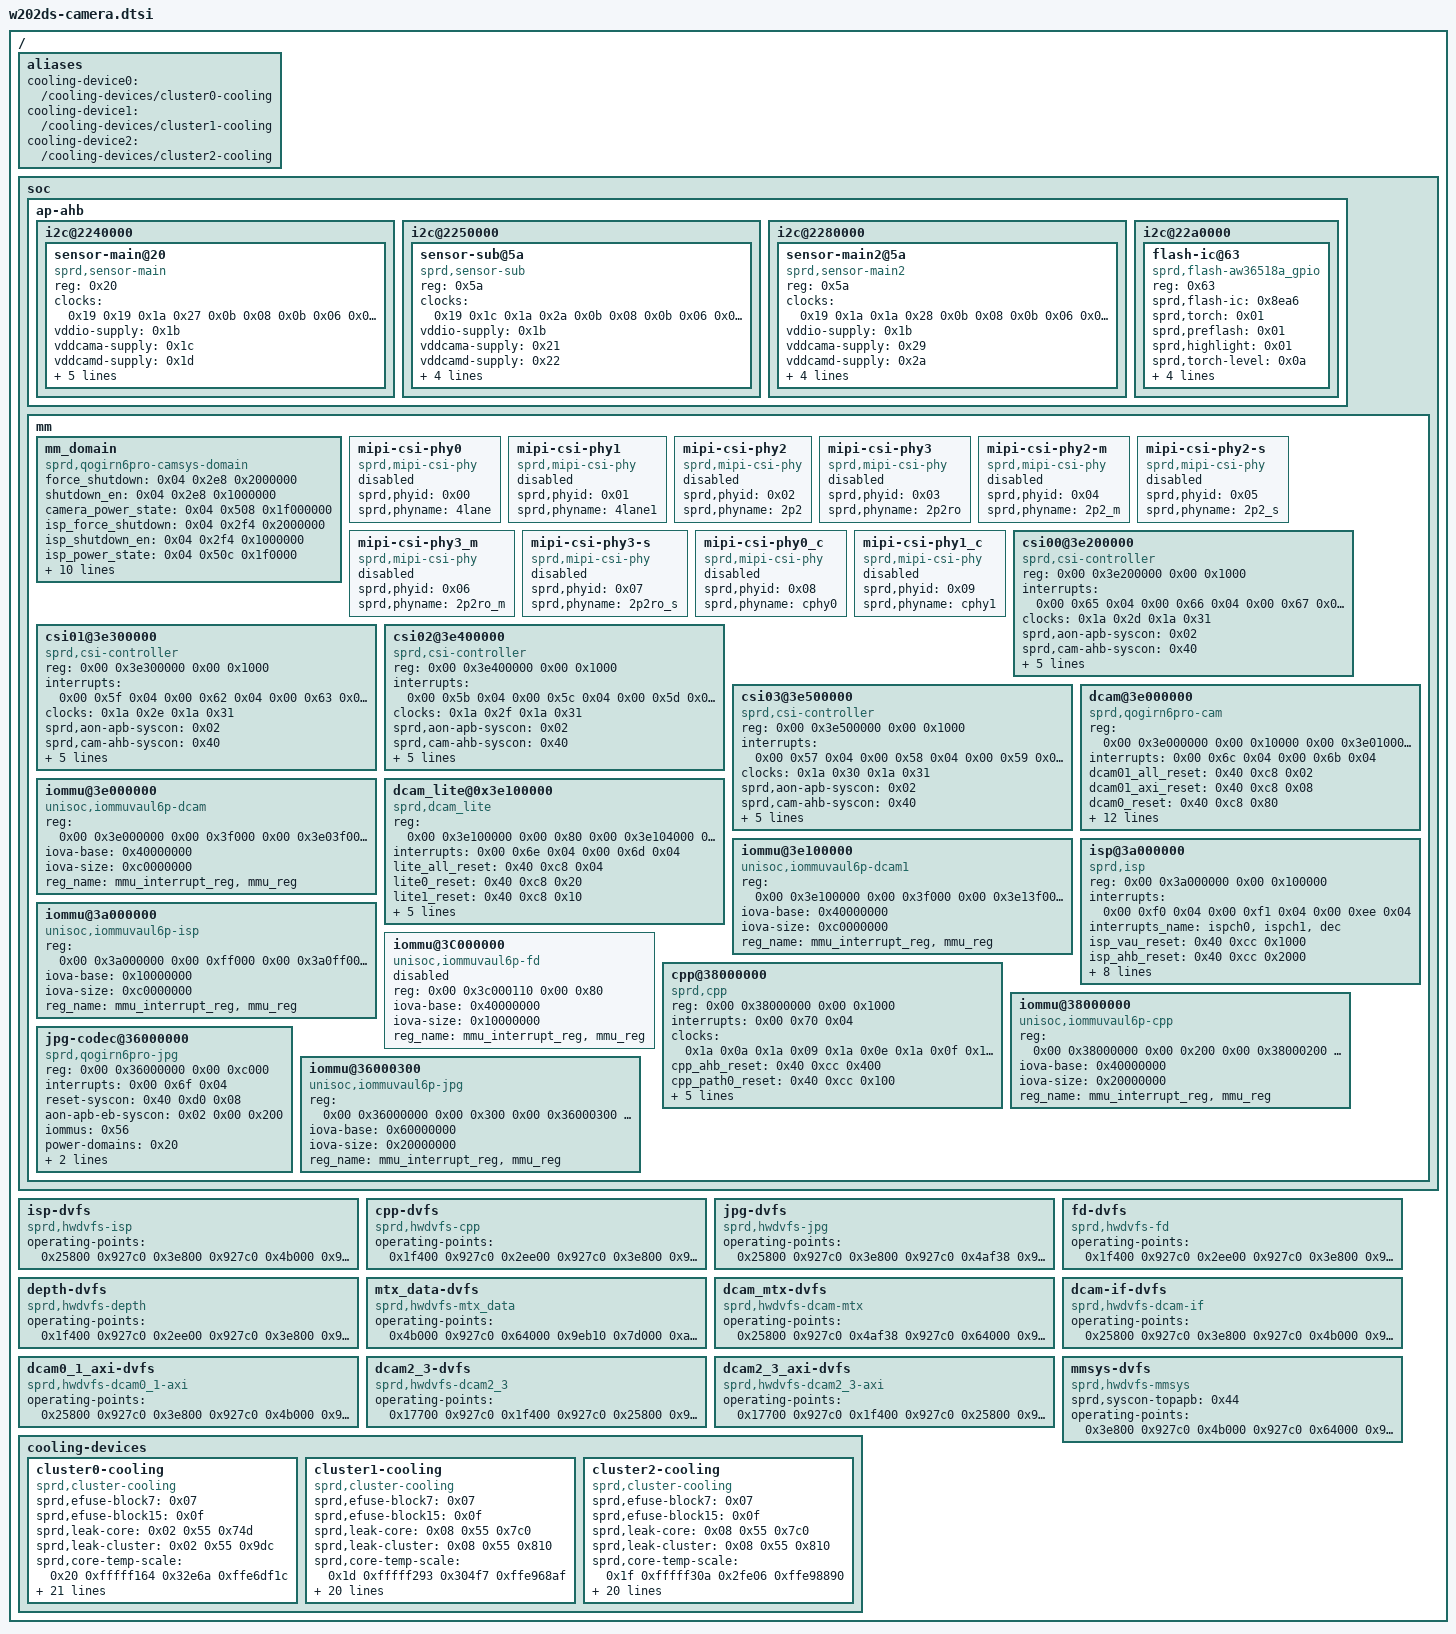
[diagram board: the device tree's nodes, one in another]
// W202DS imported hardware layout; driver status is documented in ../README.md.
/ {
	aliases {
		cooling-device0 = "/cooling-devices/cluster0-cooling";
		cooling-device1 = "/cooling-devices/cluster1-cooling";
		cooling-device2 = "/cooling-devices/cluster2-cooling";
	};
	soc {
		ap-ahb {
			i2c@2240000 {
				sensor-main@20 {
					compatible = "sprd,sensor-main";
					reg = <0x20>;
					clock-names = "clk_src", "sensor_eb", "clk_96m", "clk_64m", "clk_51m2", "clk_48m", "clk_26m";
					clocks = <0x19 0x19 0x1a 0x27 0x0b 0x08 0x0b 0x06 0x0b 0x05 0x0b 0x04 0x09>;
					vddio-supply = <0x1b>;
					vddcama-supply = <0x1c>;
					vddcamd-supply = <0x1d>;
					vddcammot-supply = <0x1e>;
					reset-gpios = <0x0c 0x28 0x00>;
					sprd,phyid = <0x02>;
					csi = <0x1f>;
					power-domains = <0x20>;
					phandle = <0x148>;
				};
			};
			i2c@2250000 {
				sensor-sub@5a {
					compatible = "sprd,sensor-sub";
					reg = <0x5a>;
					clock-names = "clk_src", "sensor_eb", "clk_96m", "clk_64m", "clk_51m2", "clk_48m", "clk_26m";
					clocks = <0x19 0x1c 0x1a 0x2a 0x0b 0x08 0x0b 0x06 0x0b 0x05 0x0b 0x04 0x09>;
					vddio-supply = <0x1b>;
					vddcama-supply = <0x21>;
					vddcamd-supply = <0x22>;
					reset-gpios = <0x0c 0x27 0x00>;
					sprd,phyid = <0x03>;
					csi = <0x23>;
					power-domains = <0x20>;
					phandle = <0x14a>;
				};
			};
			i2c@2280000 {
				sensor-main2@5a {
					compatible = "sprd,sensor-main2";
					reg = <0x5a>;
					clock-names = "clk_src", "sensor_eb", "clk_96m", "clk_64m", "clk_51m2", "clk_48m", "clk_26m";
					clocks = <0x19 0x1a 0x1a 0x28 0x0b 0x08 0x0b 0x06 0x0b 0x05 0x0b 0x04 0x09>;
					vddio-supply = <0x1b>;
					vddcama-supply = <0x29>;
					vddcamd-supply = <0x2a>;
					reset-gpios = <0x0c 0x29 0x00>;
					sprd,phyid = <0x01>;
					csi = <0x2b>;
					power-domains = <0x20>;
					phandle = <0x14f>;
				};
			};
			i2c@22a0000 {
				flash-ic@63 {
					compatible = "sprd,flash-aw36518a_gpio";
					reg = <0x63>;
					sprd,flash-ic = <0x8ea6>;
					sprd,torch = <0x01>;
					sprd,preflash = <0x01>;
					sprd,highlight = <0x01>;
					sprd,torch-level = <0x0a>;
					sprd,preflash-level = <0x0a>;
					sprd,highlight-level = <0x0f>;
					sprd,lvfm-enable = <0x01>;
					flash-torch-en-gpios = <0x0c 0x6f 0x00>;
					phandle = <0x153>;
				};
			};
		};
		mm {
			mm_domain {
				compatible = "sprd,qogirn6pro-camsys-domain";
				force_shutdown = <0x04 0x2e8 0x2000000>;
				shutdown_en = <0x04 0x2e8 0x1000000>;
				camera_power_state = <0x04 0x508 0x1f000000>;
				isp_force_shutdown = <0x04 0x2f4 0x2000000>;
				isp_shutdown_en = <0x04 0x2f4 0x1000000>;
				isp_power_state = <0x04 0x50c 0x1f0000>;
				dcam_force_shutdown = <0x04 0x2ec 0x2000000>;
				dcam_shutdown_en = <0x04 0x2ec 0x1000000>;
				dcam_power_state = <0x04 0x50c 0x1f>;
				aon_apb_mm_eb = <0x02 0x00 0x200>;
				mm_ahb_dvfs_en = <0x40 0x00 0x08>;
				cam_sw_dvfs_ack = <0x41 0x38 0x100>;
				cam_sw_dvfs_volt = <0x41 0x38 0xf0>;
				cam_sw_dvfs_req = <0x41 0x38 0x01>;
				clock-names = "clk_mm_eb", "clk_ckg_en", "clk_mm_mtx_data_en", "clk_mm_mtx_data", "clk_blk_cfg_en", "sys_cfg_mtx_busmon_en", "sys_mst_busmon_en", "clk_mm_mtx_defalut", "clk_mm_mtx_parent", "clk_mm_sys_cfg", "clk_mm_sys_cfg_parent";
				clocks = <0x11 0x07 0x1a 0x01 0x1a 0x08 0x19 0x16 0x1a 0x0f 0x1a 0x05 0x1a 0x06 0x0b 0x0a 0x0b 0x0f 0x19 0x18 0x0b 0x09>;
				#power-domain-cells = <0x00>;
				status = "okay";
				phandle = <0x20>;
			};
			mipi-csi-phy0 {
				compatible = "sprd,mipi-csi-phy";
				sprd,phyid = <0x00>;
				sprd,phyname = "4lane";
				status = "disabled";
				phandle = <0x15b>;
			};
			mipi-csi-phy1 {
				compatible = "sprd,mipi-csi-phy";
				sprd,phyid = <0x01>;
				sprd,phyname = "4lane1";
				status = "disabled";
				phandle = <0x15c>;
			};
			mipi-csi-phy2 {
				compatible = "sprd,mipi-csi-phy";
				sprd,phyid = <0x02>;
				sprd,phyname = "2p2";
				status = "disabled";
				phandle = <0x15d>;
			};
			mipi-csi-phy3 {
				compatible = "sprd,mipi-csi-phy";
				sprd,phyid = <0x03>;
				sprd,phyname = "2p2ro";
				status = "disabled";
				phandle = <0x15e>;
			};
			mipi-csi-phy2-m {
				compatible = "sprd,mipi-csi-phy";
				sprd,phyid = <0x04>;
				sprd,phyname = "2p2_m";
				status = "disabled";
				phandle = <0x15f>;
			};
			mipi-csi-phy2-s {
				compatible = "sprd,mipi-csi-phy";
				sprd,phyid = <0x05>;
				sprd,phyname = "2p2_s";
				status = "disabled";
				phandle = <0x160>;
			};
			mipi-csi-phy3_m {
				compatible = "sprd,mipi-csi-phy";
				sprd,phyid = <0x06>;
				sprd,phyname = "2p2ro_m";
				status = "disabled";
				phandle = <0x161>;
			};
			mipi-csi-phy3-s {
				compatible = "sprd,mipi-csi-phy";
				sprd,phyid = <0x07>;
				sprd,phyname = "2p2ro_s";
				status = "disabled";
				phandle = <0x162>;
			};
			mipi-csi-phy0_c {
				compatible = "sprd,mipi-csi-phy";
				sprd,phyid = <0x08>;
				sprd,phyname = "cphy0";
				status = "disabled";
				phandle = <0x163>;
			};
			mipi-csi-phy1_c {
				compatible = "sprd,mipi-csi-phy";
				sprd,phyid = <0x09>;
				sprd,phyname = "cphy1";
				status = "disabled";
				phandle = <0x164>;
			};
			csi00@3e200000 {
				compatible = "sprd,csi-controller";
				reg = <0x00 0x3e200000 0x00 0x1000>;
				interrupts = <0x00 0x65 0x04 0x00 0x66 0x04 0x00 0x67 0x04 0x00 0x68 0x04>;
				clock-names = "clk_csi_eb", "mipi_csi_src_eb";
				clocks = <0x1a 0x2d 0x1a 0x31>;
				sprd,aon-apb-syscon = <0x02>;
				sprd,cam-ahb-syscon = <0x40>;
				sprd,anlg_phy_g4l_controller = <0x47>;
				sprd,anlg_phy_g4_controller = <0x48>;
				sprd,csi-id = <0x00>;
				sprd,dcam-id = <0x00>;
				sprd,ip-version = <0x301>;
				status = "okay";
				phandle = <0x166>;
			};
			csi01@3e300000 {
				compatible = "sprd,csi-controller";
				reg = <0x00 0x3e300000 0x00 0x1000>;
				interrupts = <0x00 0x5f 0x04 0x00 0x62 0x04 0x00 0x63 0x04 0x00 0x64 0x04>;
				clock-names = "clk_csi_eb", "mipi_csi_src_eb";
				clocks = <0x1a 0x2e 0x1a 0x31>;
				sprd,aon-apb-syscon = <0x02>;
				sprd,cam-ahb-syscon = <0x40>;
				sprd,anlg_phy_g4_controller = <0x48>;
				sprd,anlg_phy_g4l_controller = <0x47>;
				sprd,csi-id = <0x01>;
				sprd,dcam-id = <0x01>;
				sprd,ip-version = <0x301>;
				status = "okay";
				phandle = <0x2b>;
			};
			csi02@3e400000 {
				compatible = "sprd,csi-controller";
				reg = <0x00 0x3e400000 0x00 0x1000>;
				interrupts = <0x00 0x5b 0x04 0x00 0x5c 0x04 0x00 0x5d 0x04 0x00 0x5e 0x04>;
				clock-names = "clk_csi_eb", "mipi_csi_src_eb";
				clocks = <0x1a 0x2f 0x1a 0x31>;
				sprd,aon-apb-syscon = <0x02>;
				sprd,cam-ahb-syscon = <0x40>;
				sprd,anlg_phy_g4l_controller = <0x47>;
				sprd,anlg_phy_g4_controller = <0x48>;
				sprd,csi-id = <0x02>;
				sprd,dcam-id = <0x02>;
				sprd,ip-version = <0x301>;
				status = "okay";
				phandle = <0x1f>;
			};
			csi03@3e500000 {
				compatible = "sprd,csi-controller";
				reg = <0x00 0x3e500000 0x00 0x1000>;
				interrupts = <0x00 0x57 0x04 0x00 0x58 0x04 0x00 0x59 0x04 0x00 0x5a 0x04>;
				clock-names = "clk_csi_eb", "mipi_csi_src_eb";
				clocks = <0x1a 0x30 0x1a 0x31>;
				sprd,aon-apb-syscon = <0x02>;
				sprd,cam-ahb-syscon = <0x40>;
				sprd,anlg_phy_g4_controller = <0x48>;
				sprd,anlg_phy_g4l_controller = <0x47>;
				sprd,csi-id = <0x03>;
				sprd,dcam-id = <0x03>;
				sprd,ip-version = <0x301>;
				status = "okay";
				phandle = <0x23>;
			};
			dcam@3e000000 {
				compatible = "sprd,qogirn6pro-cam";
				reg = <0x00 0x3e000000 0x00 0x10000 0x00 0x3e010000 0x00 0x10000 0x00 0x3e030000 0x00 0xb0 0x00 0x3e038000 0x00 0x40>;
				reg-names = "dcam0_reg", "dcam1_reg", "dcam01_axi_ctrl_reg", "fmcu_ctrl_reg";
				interrupts = <0x00 0x6c 0x04 0x00 0x6b 0x04>;
				interrupt-names = "dcam0", "dcam1";
				dcam01_all_reset = <0x40 0xc8 0x02>;
				dcam01_axi_reset = <0x40 0xc8 0x08>;
				dcam0_reset = <0x40 0xc8 0x80>;
				dcam1_reset = <0x40 0xc8 0x40>;
				clock-names = "dcam_eb", "dcam_blk_cfg_en", "dcam_tck_en", "dcam_mtx_en", "dcam_clk", "dcam_clk_parent", "dcam_axi_clk", "dcam_axi_clk_parent", "dcam_mtx_clk", "dcam_mtx_clk_parent", "dcam_blk_cfg_clk", "dcam_blk_cfg_clk_parent";
				clocks = <0x1a 0x21 0x1a 0x26 0x1a 0x2c 0x1a 0x24 0x19 0x0a 0x0b 0x0f 0x19 0x0b 0x0b 0x0f 0x19 0x14 0x0b 0x0f 0x19 0x15 0x0b 0x09>;
				sprd,cam-ahb-syscon = <0x40>;
				sprd,csi-switch = <0x49>;
				sprd,isp = <0x4a>;
				sprd,dcam-lite = <0x4b>;
				sprd,dcam-count = <0x02>;
				sprd,dcam-superzoom = <0x02>;
				sprd,project-id = <0x04>;
				iommus = <0x4c>;
				power-domains = <0x20>;
				status = "okay";
				phandle = <0x167>;
			};
			iommu@3e000000 {
				compatible = "unisoc,iommuvaul6p-dcam";
				reg = <0x00 0x3e000000 0x00 0x3f000 0x00 0x3e03f000 0x00 0xb0>;
				iova-base = <0x40000000>;
				iova-size = <0xc0000000>;
				reg_name = "mmu_interrupt_reg", "mmu_reg";
				status = "okay";
				#iommu-cells = <0x00>;
				phandle = <0x4c>;
			};
			dcam_lite@0x3e100000 {
				compatible = "sprd,dcam_lite";
				reg = <0x00 0x3e100000 0x00 0x80 0x00 0x3e104000 0x00 0x80 0x00 0x3e108000 0x00 0x50>;
				reg-names = "dcam2_reg", "dcam3_reg", "dcam23_axi_ctrl_reg";
				interrupts = <0x00 0x6e 0x04 0x00 0x6d 0x04>;
				interrupt-names = "dcam2", "dcam3";
				lite_all_reset = <0x40 0xc8 0x04>;
				lite0_reset = <0x40 0xc8 0x20>;
				lite1_reset = <0x40 0xc8 0x10>;
				clock-names = "dcam_lite_eb", "dcam_lite_mtx_en", "dcam_lite_clk", "dcam_lite_clk_parent", "dcam_lite_axi_clk", "dcam_lite_axi_clk_parent";
				clocks = <0x1a 0x22 0x1a 0x25 0x19 0x0c 0x0b 0x0c 0x19 0x0d 0x0b 0x0c>;
				sprd,dcam-lite-count = <0x02>;
				iommus = <0x4d>;
				power-domains = <0x20>;
				status = "okay";
				phandle = <0x4b>;
			};
			iommu@3e100000 {
				compatible = "unisoc,iommuvaul6p-dcam1";
				reg = <0x00 0x3e100000 0x00 0x3f000 0x00 0x3e13f000 0x00 0xb0>;
				iova-base = <0x40000000>;
				iova-size = <0xc0000000>;
				reg_name = "mmu_interrupt_reg", "mmu_reg";
				status = "okay";
				#iommu-cells = <0x00>;
				phandle = <0x4d>;
			};
			isp@3a000000 {
				compatible = "sprd,isp";
				reg = <0x00 0x3a000000 0x00 0x100000>;
				interrupts = <0x00 0xf0 0x04 0x00 0xf1 0x04 0x00 0xee 0x04>;
				interrupts_name = "ispch0", "ispch1", "dec";
				isp_vau_reset = <0x40 0xcc 0x1000>;
				isp_ahb_reset = <0x40 0xcc 0x2000>;
				reset = <0x40 0xcc 0x4000>;
				sys_h2p_db_soft_rst = <0x40 0xd0 0x04>;
				clock-names = "isp_eb", "isp_mtx_en", "isp_tck_en", "isp_clk", "isp_clk_153m6", "isp_clk_256m", "isp_clk_307m2", "isp_clk_409m6", "isp_clk_512m", "isp_clk_parent";
				clocks = <0x1a 0x09 0x1a 0x0e 0x1a 0x13 0x19 0x06 0x0b 0x0a 0x0b 0x0c 0x0b 0x0d 0x0b 0x15 0x0b 0x0f 0x0b 0x0f>;
				sprd,cam-ahb-syscon = <0x40>;
				sprd,isp-count = <0x01>;
				iommus = <0x4e>;
				power-domains = <0x20>;
				status = "okay";
				phandle = <0x4a>;
			};
			iommu@3a000000 {
				compatible = "unisoc,iommuvaul6p-isp";
				reg = <0x00 0x3a000000 0x00 0xff000 0x00 0x3a0ff000 0x00 0xb0>;
				iova-base = <0x10000000>;
				iova-size = <0xc0000000>;
				reg_name = "mmu_interrupt_reg", "mmu_reg";
				status = "okay";
				#iommu-cells = <0x00>;
				phandle = <0x4e>;
			};
			iommu@3C000000 {
				compatible = "unisoc,iommuvaul6p-fd";
				reg = <0x00 0x3c000110 0x00 0x80>;
				iova-base = <0x40000000>;
				iova-size = <0x10000000>;
				reg_name = "mmu_interrupt_reg", "mmu_reg";
				status = "disabled";
				#iommu-cells = <0x00>;
				phandle = <0x168>;
			};
			cpp@38000000 {
				compatible = "sprd,cpp";
				reg = <0x00 0x38000000 0x00 0x1000>;
				interrupts = <0x00 0x70 0x04>;
				clock-names = "cpp_eb", "cpp_axi_eb", "isp_mtx_en", "isp_blk_cfg_en", "cpp_clk", "cpp_clk_parent";
				clocks = <0x1a 0x0a 0x1a 0x09 0x1a 0x0e 0x1a 0x0f 0x19 0x07 0x0b 0x0e>;
				cpp_ahb_reset = <0x40 0xcc 0x400>;
				cpp_path0_reset = <0x40 0xcc 0x100>;
				cpp_path1_reset = <0x40 0xcc 0x80>;
				cpp_dma_soft_set = <0x40 0xcc 0x40>;
				sprd,cam-ahb-syscon = <0x40>;
				iommus = <0x4f>;
				power-domains = <0x20>;
				status = "okay";
				phandle = <0x169>;
			};
			iommu@38000000 {
				compatible = "unisoc,iommuvaul6p-cpp";
				reg = <0x00 0x38000000 0x00 0x200 0x00 0x38000200 0x00 0x80>;
				iova-base = <0x40000000>;
				iova-size = <0x20000000>;
				reg_name = "mmu_interrupt_reg", "mmu_reg";
				status = "okay";
				#iommu-cells = <0x00>;
				phandle = <0x4f>;
			};
			jpg-codec@36000000 {
				compatible = "sprd,qogirn6pro-jpg";
				reg = <0x00 0x36000000 0x00 0xc000>;
				interrupts = <0x00 0x6f 0x04>;
				reset-syscon = <0x40 0xd0 0x08>;
				aon-apb-eb-syscon = <0x02 0x00 0x200>;
				iommus = <0x56>;
				power-domains = <0x20>;
				status = "okay";
				clock-names = "jpg_domain_eb", "jpg_dev_eb", "jpg_ckg_eb", "jpg_clk", "clk_src_153m6", "clk_src_256m", "clk_src_307m2", "clk_src_409m6", "clk_src_512m";
				clocks = <0x11 0x07 0x1a 0x00 0x1a 0x01 0x19 0x17 0x0b 0x0a 0x0b 0x0c 0x0b 0x0d 0x0b 0x15 0x0b 0x0f>;
				phandle = <0x16d>;
			};
			iommu@36000300 {
				compatible = "unisoc,iommuvaul6p-jpg";
				reg = <0x00 0x36000000 0x00 0x300 0x00 0x36000300 0x00 0x80>;
				iova-base = <0x60000000>;
				iova-size = <0x20000000>;
				reg_name = "mmu_interrupt_reg", "mmu_reg";
				status = "okay";
				#iommu-cells = <0x00>;
				phandle = <0x56>;
			};
		};
	};
	isp-dvfs {
		compatible = "sprd,hwdvfs-isp";
		operating-points = <0x25800 0x927c0 0x3e800 0x927c0 0x4b000 0x927c0 0x64000 0x9eb10 0x7d000 0xb71b0>;
		phandle = <0x217>;
	};
	cpp-dvfs {
		compatible = "sprd,hwdvfs-cpp";
		operating-points = <0x1f400 0x927c0 0x2ee00 0x927c0 0x3e800 0x927c0 0x4b000 0x9eb10 0x5dc00 0xaae60>;
		phandle = <0x218>;
	};
	jpg-dvfs {
		compatible = "sprd,hwdvfs-jpg";
		operating-points = <0x25800 0x927c0 0x3e800 0x927c0 0x4af38 0x927c0 0x64000 0x9eb10 0x7d000 0xaae60>;
		phandle = <0x219>;
	};
	fd-dvfs {
		compatible = "sprd,hwdvfs-fd";
		operating-points = <0x1f400 0x927c0 0x2ee00 0x927c0 0x3e800 0x927c0 0x4b000 0x9eb10 0x5dc00 0xaae60>;
		phandle = <0x21a>;
	};
	depth-dvfs {
		compatible = "sprd,hwdvfs-depth";
		operating-points = <0x1f400 0x927c0 0x2ee00 0x927c0 0x3e800 0x927c0 0x4b000 0x9eb10 0x5dc00 0xaae60>;
		phandle = <0x21b>;
	};
	mtx_data-dvfs {
		compatible = "sprd,hwdvfs-mtx_data";
		operating-points = <0x4b000 0x927c0 0x64000 0x9eb10 0x7d000 0xaae60>;
		phandle = <0x21c>;
	};
	dcam_mtx-dvfs {
		compatible = "sprd,hwdvfs-dcam-mtx";
		operating-points = <0x25800 0x927c0 0x4af38 0x927c0 0x64000 0x9eb10 0x7d000 0xaae60>;
		phandle = <0x21d>;
	};
	dcam-if-dvfs {
		compatible = "sprd,hwdvfs-dcam-if";
		operating-points = <0x25800 0x927c0 0x3e800 0x927c0 0x4b000 0x927c0 0x64000 0x9eb10 0x7d000 0xaae60>;
		phandle = <0x21e>;
	};
	dcam0_1_axi-dvfs {
		compatible = "sprd,hwdvfs-dcam0_1-axi";
		operating-points = <0x25800 0x927c0 0x3e800 0x927c0 0x4b000 0x927c0 0x64000 0x9eb10 0x7d000 0xaae60>;
		phandle = <0x21f>;
	};
	dcam2_3-dvfs {
		compatible = "sprd,hwdvfs-dcam2_3";
		operating-points = <0x17700 0x927c0 0x1f400 0x927c0 0x25800 0x927c0 0x2ee00 0x9eb10 0x3e800 0xaae60>;
		phandle = <0x220>;
	};
	dcam2_3_axi-dvfs {
		compatible = "sprd,hwdvfs-dcam2_3-axi";
		operating-points = <0x17700 0x927c0 0x1f400 0x927c0 0x25800 0x927c0 0x2ee00 0x9eb10 0x3e800 0xaae60>;
		phandle = <0x221>;
	};
	mmsys-dvfs {
		compatible = "sprd,hwdvfs-mmsys";
		sprd,syscon-topapb = <0x44>;
		operating-points = <0x3e800 0x927c0 0x4b000 0x927c0 0x64000 0x9eb10 0x7d000 0xb71b0>;
		phandle = <0x225>;
	};
	cooling-devices {
		cluster0-cooling {
			compatible = "sprd,cluster-cooling";
			#cooling-cells = <0x02>;
			sprd,efuse-block7 = <0x07>;
			sprd,efuse-block15 = <0x0f>;
			sprd,leak-core = <0x02 0x55 0x74d>;
			sprd,leak-cluster = <0x02 0x55 0x9dc>;
			sprd,core-temp-scale = <0x20 0xfffff164 0x32e6a 0xffe6df1c>;
			sprd,core-voltage-scale = <0x22c 0xfffffb9b 0x365 0xffffff38>;
			sprd,cluster-temp-scale = <0x15 0xfffff8b1 0x1aec9 0xfffb5fb5>;
			sprd,cluster-voltage-scale = <0x607 0xfffff328 0x973 0xfffffdc2>;
			sprd,efuse-switch = <0x00>;
			sprd,hotplug-period = <0x0a>;
			sprd,min-cpufreq = "", "\t`";
			sprd,min-cpunum = <0x01>;
			sprd,max-temp = <0x15f90>;
			sprd,core-base = <0x873>;
			sprd,cluster-base = <0x24be>;
			sprd,dynamic-core = <0x306 0x3e8 0x3e8>;
			sprd,dynamic-cluster = <0x608 0x3e8 0x3e8>;
			sprd,sensor-names = "ank0-thmzone", "ank1-thmzone", "ank2-thmzone", "ank3-thmzone", "ank4-thmzone", "ank5-thmzone";
			sprd,cii-per-core-tp = <0x19a28 0x186a0 0x17318 0x15f90>;
			sprd,cii-max-tp-core = <0x15f90>;
			phandle = <0x11a>;
		};
		cluster1-cooling {
			compatible = "sprd,cluster-cooling";
			#cooling-cells = <0x02>;
			sprd,efuse-block7 = <0x07>;
			sprd,efuse-block15 = <0x0f>;
			sprd,leak-core = <0x08 0x55 0x7c0>;
			sprd,leak-cluster = <0x08 0x55 0x810>;
			sprd,core-temp-scale = <0x1d 0xfffff293 0x304f7 0xffe968af>;
			sprd,core-voltage-scale = <0x294 0xfffffaba 0x404 0xffffff12>;
			sprd,cluster-temp-scale = <0x15 0xfffff8b1 0x1aec9 0xfffb5fb5>;
			sprd,cluster-voltage-scale = <0x607 0xfffff328 0x973 0xfffffdc2>;
			sprd,efuse-switch = <0x00>;
			sprd,hotplug-period = <0x0a>;
			sprd,min-cpufreq = <0x12c000>;
			sprd,min-cpunum = <0x00>;
			sprd,max-temp = <0x14c08>;
			sprd,core-base = <0x35c4>;
			sprd,cluster-base = <0x24be>;
			sprd,dynamic-core = <0xe12 0x3e8 0x3e8>;
			sprd,dynamic-cluster = <0x608 0x3e8 0x3e8>;
			sprd,sensor-names = "prometheus6-tzone0", "prometheus7-thmzone";
			sprd,cii-per-core-tp = <0x14c08 0x13880 0x124f8 0x11170>;
			sprd,cii-max-tp-core = <0x124f8>;
			phandle = <0x11b>;
		};
		cluster2-cooling {
			compatible = "sprd,cluster-cooling";
			#cooling-cells = <0x02>;
			sprd,efuse-block7 = <0x07>;
			sprd,efuse-block15 = <0x0f>;
			sprd,leak-core = <0x08 0x55 0x7c0>;
			sprd,leak-cluster = <0x08 0x55 0x810>;
			sprd,core-temp-scale = <0x1f 0xfffff30a 0x2fe06 0xffe98890>;
			sprd,core-voltage-scale = <0x22c 0xfffffb9b 0x365 0xffffff38>;
			sprd,cluster-temp-scale = <0x15 0xfffff8b1 0x1aec9 0xfffb5fb5>;
			sprd,cluster-voltage-scale = <0x607 0xfffff328 0x973 0xfffffdc2>;
			sprd,efuse-switch = <0x00>;
			sprd,hotplug-period = <0x0a>;
			sprd,min-cpufreq = <0x12c000>;
			sprd,min-cpunum = <0x00>;
			sprd,max-temp = <0x14c08>;
			sprd,core-base = <0x3ea0>;
			sprd,cluster-base = <0x24be>;
			sprd,dynamic-core = <0x117f 0x3e8 0x3e8>;
			sprd,dynamic-cluster = <0x608 0x3e8 0x3e8>;
			sprd,sensor-names = "prometheus6-tzone0", "prometheus7-thmzone";
			sprd,cii-per-core-tp = <0x14c08 0x13880 0x124f8 0x11170>;
			sprd,cii-max-tp-core = <0x124f8>;
			phandle = <0x11c>;
		};
	};
	__symbols__ {
		sensor_main = "/soc/ap-ahb/i2c@2240000/sensor-main@20";
		sensor_sub = "/soc/ap-ahb/i2c@2250000/sensor-sub@5a";
		sensor_main2 = "/soc/ap-ahb/i2c@2280000/sensor-main2@5a";
		flash_ic = "/soc/ap-ahb/i2c@22a0000/flash-ic@63";
		mm_domain = "/soc/mm/mm_domain";
		mipi_csi_phy0 = "/soc/mm/mipi-csi-phy0";
		mipi_csi_phy1 = "/soc/mm/mipi-csi-phy1";
		mipi_csi_phy2 = "/soc/mm/mipi-csi-phy2";
		mipi_csi_phy3 = "/soc/mm/mipi-csi-phy3";
		mipi_csi_phy2_m = "/soc/mm/mipi-csi-phy2-m";
		mipi_csi_phy2_s = "/soc/mm/mipi-csi-phy2-s";
		mipi_csi_phy3_m = "/soc/mm/mipi-csi-phy3_m";
		mipi_csi_phy3_s = "/soc/mm/mipi-csi-phy3-s";
		mipi_csi_phy0_c = "/soc/mm/mipi-csi-phy0_c";
		mipi_csi_phy1_c = "/soc/mm/mipi-csi-phy1_c";
		csi0 = "/soc/mm/csi00@3e200000";
		csi1 = "/soc/mm/csi01@3e300000";
		csi2 = "/soc/mm/csi02@3e400000";
		csi3 = "/soc/mm/csi03@3e500000";
		dcam = "/soc/mm/dcam@3e000000";
		iommu_dcam = "/soc/mm/iommu@3e000000";
		dcam_lite = "/soc/mm/dcam_lite@0x3e100000";
		iommu_dcam_lite = "/soc/mm/iommu@3e100000";
		isp = "/soc/mm/isp@3a000000";
		iommu_isp = "/soc/mm/iommu@3a000000";
		iommu_fd = "/soc/mm/iommu@3C000000";
		cpp = "/soc/mm/cpp@38000000";
		iommu_cpp = "/soc/mm/iommu@38000000";
		jpg = "/soc/mm/jpg-codec@36000000";
		iommu_jpg = "/soc/mm/iommu@36000300";
		isp_dvfs = "/isp-dvfs";
		cpp_dvfs = "/cpp-dvfs";
		jpg_dvfs = "/jpg-dvfs";
		fd_dvfs = "/fd-dvfs";
		depth_dvfs = "/depth-dvfs";
		mtx_data_dvfs = "/mtx_data-dvfs";
		dcam_mtx_dvfs = "/dcam_mtx-dvfs";
		dcam_if_dvfs = "/dcam-if-dvfs";
		dcam0_1_axi_dvfs = "/dcam0_1_axi-dvfs";
		dcam2_3_dvfs = "/dcam2_3-dvfs";
		dcam2_3_axi_dvfs = "/dcam2_3_axi-dvfs";
		mmsys_dvfs = "/mmsys-dvfs";
		cluster0_cooling = "/cooling-devices/cluster0-cooling";
		cluster1_cooling = "/cooling-devices/cluster1-cooling";
		cluster2_cooling = "/cooling-devices/cluster2-cooling";
	};
};
